AUTOSAR XML (schema 00052)
package /katech/AdaptiveApplicationSwComponentTypes
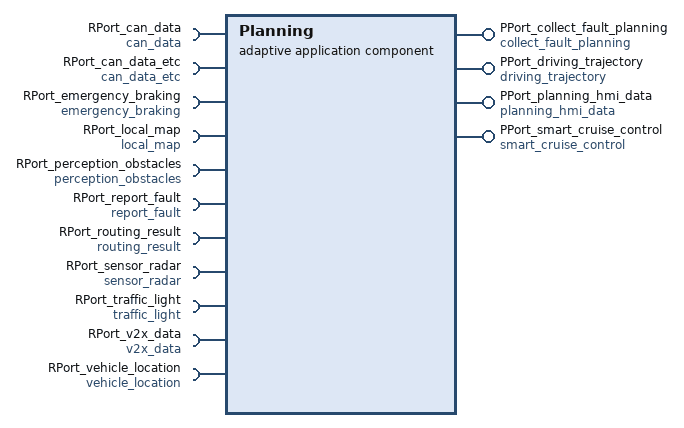
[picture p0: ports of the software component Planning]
  adaptive application sw component type Planning
    4 x provide port:
      PPort_collect_fault_planning: provided-interface=collect_fault_planning
      PPort_driving_trajectory: provided-interface=driving_trajectory
      PPort_planning_hmi_data: provided-interface=planning_hmi_data
      PPort_smart_cruise_control: provided-interface=smart_cruise_control
    11 x require port:
      RPort_can_data: required-interface=can_data
      RPort_can_data_etc: required-interface=can_data_etc
      RPort_emergency_braking: required-interface=emergency_braking
      RPort_local_map: required-interface=local_map
      RPort_perception_obstacles: required-interface=perception_obstacles
      RPort_report_fault: required-interface=report_fault
      RPort_routing_result: required-interface=routing_result
      RPort_sensor_radar: required-interface=sensor_radar
      RPort_traffic_light: required-interface=traffic_light
      RPort_v2x_data: required-interface=v2x_data
      RPort_vehicle_location: required-interface=vehicle_location
package /katech/Executables
  executable Planning: category=APPLICATION_LEVEL, minimum-timer-granularity=1000
    root sw component prototype Planning: application-type=Planning
